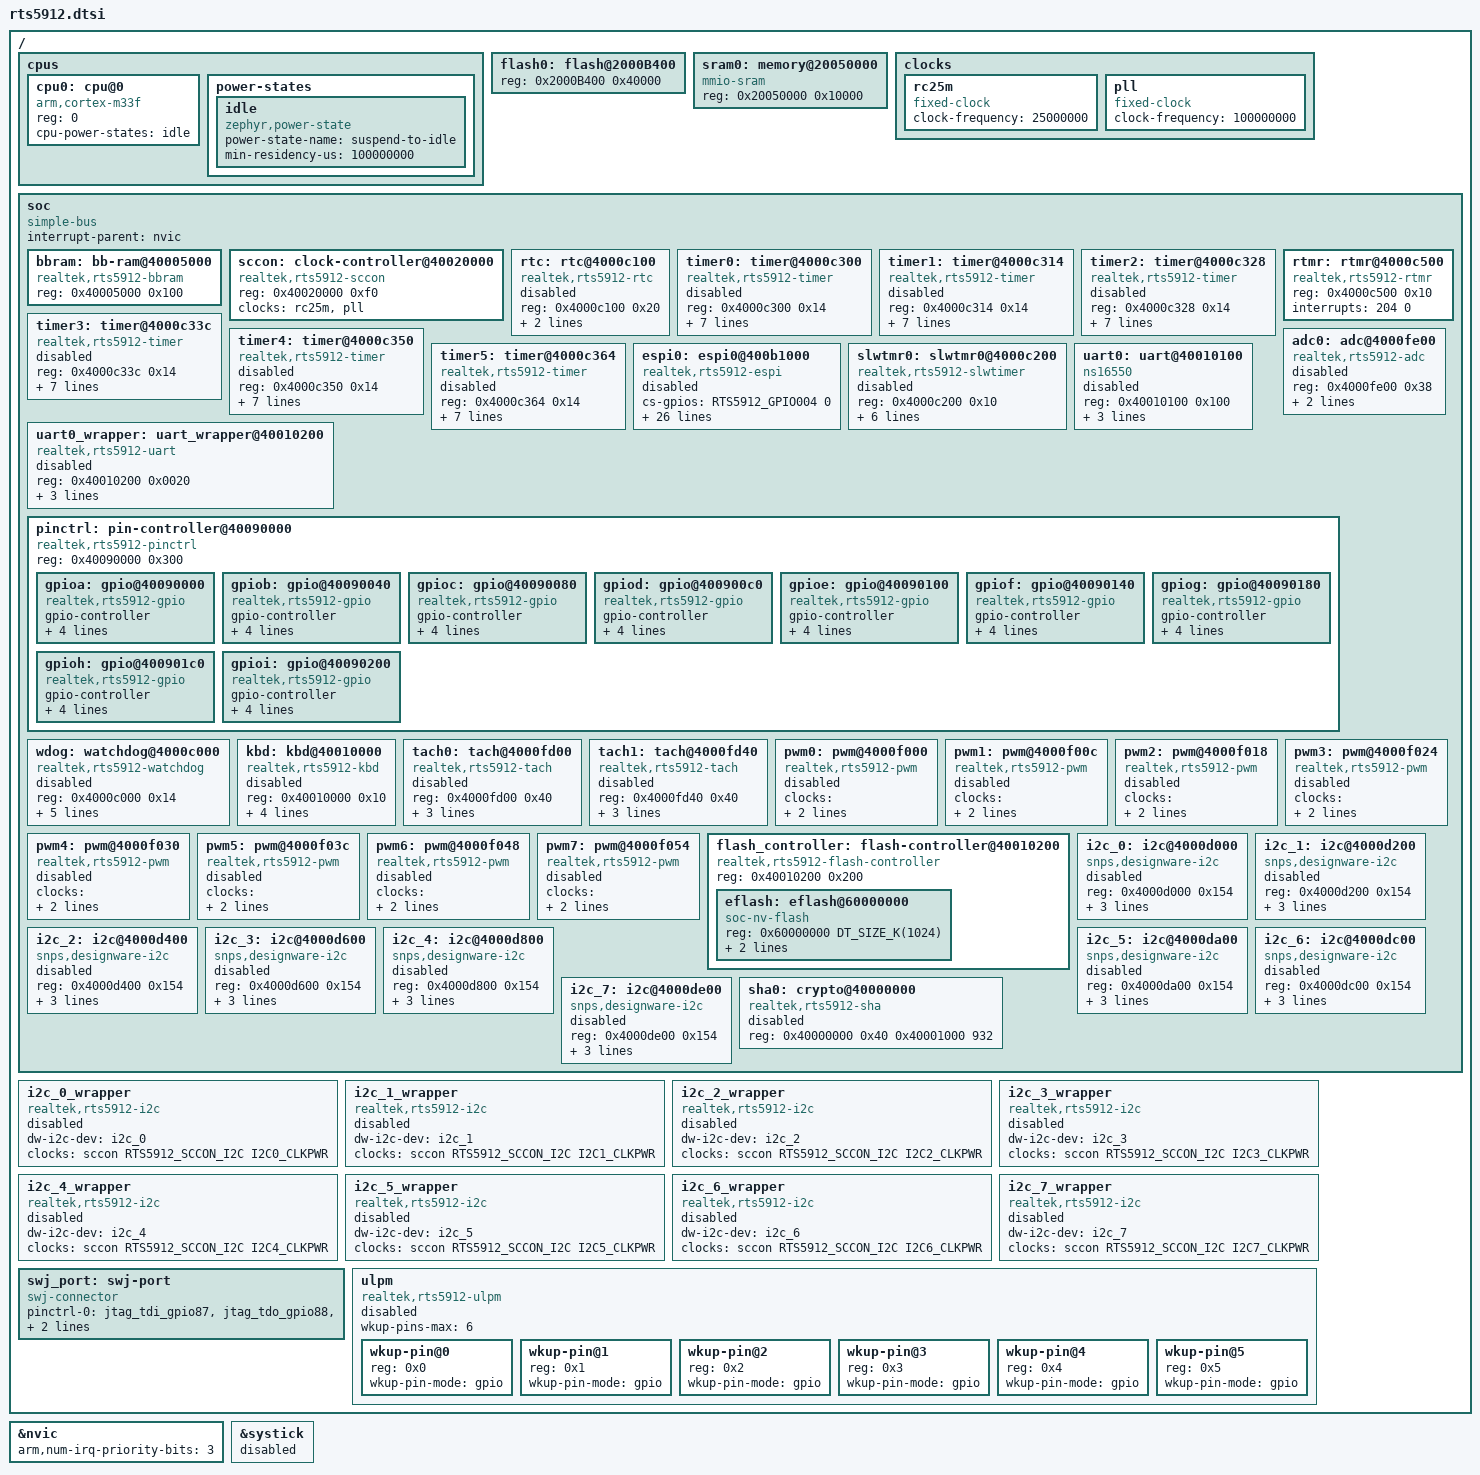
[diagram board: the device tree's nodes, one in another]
/*
 * SPDX-License-Identifier: Apache-2.0
 *
 * Copyright (c) 2024 Realtek Semiconductor Corporation, SIBG-SD7
 *
 */

#include <arm/armv8-m.dtsi>
#include <zephyr/dt-bindings/adc/adc.h>
#include <zephyr/dt-bindings/clock/rts5912_clock.h>
#include <zephyr/dt-bindings/gpio/realtek-gpio.h>
#include <zephyr/dt-bindings/pwm/pwm.h>
#include <mem.h>
#include <zephyr/dt-bindings/i2c/i2c.h>
#include <freq.h>
#include <zephyr/dt-bindings/gpio/realtek-gpio.h>

/ {
	cpus {
		#address-cells = <1>;
		#size-cells = <0>;

		cpu0: cpu@0 {
			compatible = "arm,cortex-m33f";
			reg = <0>;
			cpu-power-states = <&idle>;
		};

		power-states {
			idle: idle {
				compatible = "zephyr,power-state";
				power-state-name = "suspend-to-idle";
				min-residency-us = <100000000>;
			};
		};
	};

	flash0: flash@2000B400 {
		reg = <0x2000B400 0x40000>;
	};

	sram0: memory@20050000 {
		compatible = "mmio-sram";
		reg = <0x20050000 0x10000>;
	};

	clocks {
		rc25m: rc25m {
			compatible = "fixed-clock";
			clock-frequency = <25000000>;
			#clock-cells = <0>;
		};

		pll: pll {
			compatible = "fixed-clock";
			clock-frequency = <100000000>;
			#clock-cells = <0>;
		};
	};

	soc {
		#address-cells = <1>;
		#size-cells = <1>;
		compatible = "simple-bus";
		interrupt-parent = <&nvic>;
		ranges;

		bbram: bb-ram@40005000 {
			compatible = "realtek,rts5912-bbram";
			reg = <0x40005000 0x100>;
			status = "okay";
		};

		sccon: clock-controller@40020000 {
			compatible = "realtek,rts5912-sccon";
			reg = <0x40020000 0xf0>;
			#clock-cells = <2>;
			clocks = <&rc25m>, <&pll>;
			clock-names = "rc25m", "pll";
		};

		rtc: rtc@4000c100 {
			compatible = "realtek,rts5912-rtc";
			reg = <0x4000c100 0x20>;
			clocks = <&sccon RTS5912_SCCON_PERIPH_GRP2 PERIPH_GRP2_RTC_CLKPWR>;
			clock-names = "rtc";
			status = "disabled";
		};

		timer0: timer@4000c300 {
			compatible = "realtek,rts5912-timer";
			reg = <0x4000c300 0x14>;
			interrupt-parent = <&nvic>;
			interrupts = <196 1>;
			clocks = <&sccon RTS5912_SCCON_PERIPH_GRP1 PERIPH_GRP1_TMR0_CLKPWR>;
			clock-names = "tmr32";
			max-value = <0xFFFFFFFF>;
			clock-frequency = <25000000>;
			prescaler = <0>;
			status = "disabled";
		};

		timer1: timer@4000c314 {
			compatible = "realtek,rts5912-timer";
			reg = <0x4000c314 0x14>;
			interrupt-parent = <&nvic>;
			interrupts = <197 1>;
			clocks = <&sccon RTS5912_SCCON_PERIPH_GRP1 PERIPH_GRP1_TMR1_CLKPWR>;
			clock-names = "tmr32";
			max-value = <0xFFFFFFFF>;
			clock-frequency = <25000000>;
			prescaler = <0>;
			status = "disabled";
		};

		timer2: timer@4000c328 {
			compatible = "realtek,rts5912-timer";
			reg = <0x4000c328 0x14>;
			interrupt-parent = <&nvic>;
			interrupts = <198 1>;
			clocks = <&sccon RTS5912_SCCON_PERIPH_GRP1 PERIPH_GRP1_TMR2_CLKPWR>;
			clock-names = "tmr32";
			max-value = <0xFFFFFFFF>;
			clock-frequency = <25000000>;
			prescaler = <0>;
			status = "disabled";
		};

		timer3: timer@4000c33c {
			compatible = "realtek,rts5912-timer";
			reg = <0x4000c33c 0x14>;
			interrupt-parent = <&nvic>;
			interrupts = <199 1>;
			clocks = <&sccon RTS5912_SCCON_PERIPH_GRP1 PERIPH_GRP1_TMR3_CLKPWR>;
			clock-names = "tmr32";
			max-value = <0xFFFFFFFF>;
			clock-frequency = <25000000>;
			prescaler = <0>;
			status = "disabled";
		};

		timer4: timer@4000c350 {
			compatible = "realtek,rts5912-timer";
			reg = <0x4000c350 0x14>;
			interrupt-parent = <&nvic>;
			interrupts = <200 1>;
			clocks = <&sccon RTS5912_SCCON_PERIPH_GRP1 PERIPH_GRP1_TMR4_CLKPWR>;
			clock-names = "tmr32";
			max-value = <0xFFFFFFFF>;
			clock-frequency = <25000000>;
			prescaler = <0>;
			status = "disabled";
		};

		timer5: timer@4000c364 {
			compatible = "realtek,rts5912-timer";
			reg = <0x4000c364 0x14>;
			interrupt-parent = <&nvic>;
			interrupts = <201 1>;
			clocks = <&sccon RTS5912_SCCON_PERIPH_GRP1 PERIPH_GRP1_TMR5_CLKPWR>;
			clock-names = "tmr32";
			max-value = <0xFFFFFFFF>;
			clock-frequency = <25000000>;
			prescaler = <0>;
			status = "disabled";
		};

		espi0: espi0@400b1000 {
			compatible = "realtek,rts5912-espi";
			cs-gpios = <RTS5912_GPIO004 0>;
			status = "disabled";

			reg = <0x400b1000 0x200		/* espi target */
			       0x400a0400 0x01c		/* port80 */
			       0x400a0200 0x1c			/* ACPI */
			       0x400A021C 0x1C			/* PROMT0 */
			       0x400A0238 0x1C			/* PROMT1 */
			       0x400A0254 0x1C			/* PROMT2 */
			       0x400A0270 0x1C			/* PROMT3 */
			       0x40082000 0x14			/* EMI0 */
			       0x40082020 0x14			/* EMI1 */
			       0x40082040 0x14			/* EMI2 */
			       0x40082060 0x14			/* EMI3 */
			       0x40082080 0x14			/* EMI4 */
			       0x400820A0 0x14			/* EMI5 */
			       0x400820C0 0x14			/* EMI6 */
			       0x400820E0 0x14			/* EMI7 */
			       0x400a0100 0x1c			/* KBC */
			       0x400B1600 0xd0>;		/* MBX */

			reg-names = "espi_target", "port80", "acpi", "promt0", "promt1", "promt2",
				    "promt3", "emi0", "emi1", "emi2", "emi3", "emi4", "emi5",
				    "emi6", "emi7", "kbc", "mbx";

			clocks = <&sccon RTS5912_SCCON_PERIPH_GRP0 PERIPH_GRP0_ESPI_CLKPWR>,
				 <&sccon RTS5912_SCCON_PERIPH_GRP0 PERIPH_GRP0_P80_CLKPWR>,
				 <&sccon RTS5912_SCCON_PERIPH_GRP0 PERIPH_GRP0_ACPI_CLKPWR>,
				 <&sccon RTS5912_SCCON_PERIPH_GRP0 PERIPH_GRP0_PMPORT0_CLKPWR>,
				 <&sccon RTS5912_SCCON_PERIPH_GRP0 PERIPH_GRP0_PMPORT1_CLKPWR>,
				 <&sccon RTS5912_SCCON_PERIPH_GRP0 PERIPH_GRP0_PMPORT2_CLKPWR>,
				 <&sccon RTS5912_SCCON_PERIPH_GRP0 PERIPH_GRP0_PMPORT3_CLKPWR>,
				 <&sccon RTS5912_SCCON_PERIPH_GRP0 PERIPH_GRP0_EMI0_CLKPWR>,
				 <&sccon RTS5912_SCCON_PERIPH_GRP0 PERIPH_GRP0_EMI1_CLKPWR>,
				 <&sccon RTS5912_SCCON_PERIPH_GRP1 PERIPH_GRP1_EMI2_CLKPWR>,
				 <&sccon RTS5912_SCCON_PERIPH_GRP1 PERIPH_GRP1_EMI3_CLKPWR>,
				 <&sccon RTS5912_SCCON_PERIPH_GRP1 PERIPH_GRP1_EMI4_CLKPWR>,
				 <&sccon RTS5912_SCCON_PERIPH_GRP1 PERIPH_GRP1_EMI5_CLKPWR>,
				 <&sccon RTS5912_SCCON_PERIPH_GRP1 PERIPH_GRP1_EMI6_CLKPWR>,
				 <&sccon RTS5912_SCCON_PERIPH_GRP1 PERIPH_GRP1_EMI7_CLKPWR>,
				 <&sccon RTS5912_SCCON_PERIPH_GRP0 PERIPH_GRP0_KBC_CLKPWR>;

			clock-names = "espi-target", "port80", "acpi", "promt0", "promt1", "promt2",
				      "promt3", "emi0", "emi1", "emi2", "emi3", "emi4", "emi5",
				      "emi6", "emi7", "kbc";

			interrupts = <133 1>, <134 1>, <146 1>,
				     <145 1>, <144 1>, <143 1>,
				     <142 1>, <141 1>, <140 1>,
				     <139 1>, <138 1>, <137 1>,
				     <136 1>, <135 1>, <154 1>,
				     <155 1>, <156 1>, <157 1>,
				     <158 1>, <159 1>, <160 1>,
				     <161 1>, <162 1>, <163 1>,
				     <164 1>, <165 1>, <212 1>,
				     <213 1>, <214 1>, <215 1>,
				     <216 1>, <217 1>, <218 1>,
				     <219 1>, <147 1>, <148 1>,
				     <149 1>, <152 1>, <153 1>,
				     <166 1>, <220 1>;

			interrupt-names = "bus-rst", "periph-ch", "vw-ch",
					  "vw-idx2", "vw-idx3", "vw-idx7",
					  "vw-idx41", "vw-idx42", "vw-idx43",
					  "vw-idx44", "vw-idx47", "vw-idx4a",
					  "vw-idx51", "vw-idx61", "kbc_ibf",
					  "kbc_obe", "acpi_ibf", "acpi_obe",
					  "promt0_ibf", "promt0_obe", "promt1_ibf",
					  "promt1_obe", "promt2_ibf", "promt2_obe",
					  "promt3_ibf", "promt3_obe", "emi0",
					  "emi1", "emi2", "emi3",
					  "emi4", "emi5", "emi6",
					  "emi7", "oob_tx", "oob_rx",
					  "oob_chg", "maf_tr", "flash_chg",
					  "port80", "mbx";
		};

		slwtmr0: slwtmr0@4000c200 {
			compatible = "realtek,rts5912-slwtimer";
			reg = <0x4000c200 0x10>;
			interrupts = <202 1>;
			clocks = <&sccon RTS5912_SCCON_PERIPH_GRP1 PERIPH_GRP1_SLWTMR0_CLKPWR>;
			clock-names = "slwtmr";
			max-value = <0xFFFFFFFF>;
			clock-frequency = <1000000>;
			prescaler = <0>;
			status = "disabled";
		};

		rtmr: rtmr@4000c500 {
			compatible = "realtek,rts5912-rtmr";
			reg = <0x4000c500 0x10>;
			interrupts = <204 0>;
			status = "okay";
		};

		adc0: adc@4000fe00 {
			compatible = "realtek,rts5912-adc";
			reg = <0x4000fe00 0x38>;
			clocks = <&sccon RTS5912_SCCON_ADC ADC0_CLKPWR>;
			interrupts = <221 1>;
			#io-channel-cells = <1>;
			status = "disabled";
		};

		uart0: uart@40010100 {
			compatible = "ns16550";
			reg = <0x40010100 0x100>;
			reg-shift = <2>;
			clock-frequency = <DT_FREQ_M(100)>;
			interrupts = <191 1>;
			status = "disabled";
		};

		uart0_wrapper: uart_wrapper@40010200 {
			compatible = "realtek,rts5912-uart";
			reg = <0x40010200 0x0020>;
			port = <0>;
			clocks = <&sccon RTS5912_SCCON_UART UART0_CLKPWR>;
			clock-names = "uart0";
			status = "disabled";
			uart-dev = <&uart0>;
		};

		pinctrl: pin-controller@40090000 {
			compatible = "realtek,rts5912-pinctrl";
			#address-cells = <1>;
			#size-cells = <1>;
			reg = <0x40090000 0x300>;

			/* GPIO0-GPIO15 */
			gpioa: gpio@40090000 {
				compatible = "realtek,rts5912-gpio";
				gpio-controller;
				#gpio-cells = <2>;
				reg = <0x40090000 0x40>;
				ngpios = <16>;
				interrupts = <0 1 1 1 2 1 3 1
					      4 1 5 1 6 1 7 1
					      8 1 9 1 10 1 11 1
					      12 1 13 1 14 1 15 1>;
			};

			/* GPIO16-GPIO31 */
			gpiob: gpio@40090040 {
				compatible = "realtek,rts5912-gpio";
				gpio-controller;
				#gpio-cells = <2>;
				reg = <0x40090040 0x40>;
				ngpios = <16>;
				interrupts = <16 1 17 1 18 1 19 1
					      20 1 21 1 22 1 23 1
					      24 1 25 1 26 1 27 1
					      28 1 29 1 30 1 31 1>;
			};

			/* GPIO32-GPIO47 */
			gpioc: gpio@40090080 {
				compatible = "realtek,rts5912-gpio";
				gpio-controller;
				#gpio-cells = <2>;
				reg = <0x40090080 0x40>;
				ngpios = <16>;
				interrupts = <32 1 33 1 34 1 35 1
					      36 1 37 1 38 1 39 1
					      40 1 41 1 42 1 43 1
					      44 1 45 1 46 1 47 1>;
			};

			/* GPIO48-GPIO63 */
			gpiod: gpio@400900c0 {
				compatible = "realtek,rts5912-gpio";
				gpio-controller;
				#gpio-cells = <2>;
				reg = <0x400900c0 0x40>;
				ngpios = <16>;
				interrupts = <48 1 49 1 50 1 51 1
					      52 1 53 1 54 1 55 1
					      56 1 57 1 58 1 59 1
					      60 1 61 1 62 1 63 1>;
			};

			/* GPIO64-GPIO79 */
			gpioe: gpio@40090100 {
				compatible = "realtek,rts5912-gpio";
				gpio-controller;
				#gpio-cells = <2>;
				reg = <0x40090100 0x40>;
				ngpios = <16>;
				interrupts = <64 1 65 1 66 1 67 1
					      68 1 69 1 70 1 71 1
					      72 1 73 1 74 1 75 1
					      76 1 77 1 78 1 79 1>;
			};

			/* GPIO80-GPIO95 */
			gpiof: gpio@40090140 {
				compatible = "realtek,rts5912-gpio";
				gpio-controller;
				#gpio-cells = <2>;
				reg = <0x40090140 0x40>;
				ngpios = <16>;
				interrupts = <80 1 81 1 82 1 83 1
					      84 1 85 1 86 1 87 1
					      88 1 89 1 90 1 91 1
					      92 1 93 1 94 1 95 1>;
			};

			/* GPIO96-GPIO111 */
			gpiog: gpio@40090180 {
				compatible = "realtek,rts5912-gpio";
				gpio-controller;
				#gpio-cells = <2>;
				reg = <0x40090180 0x40>;
				ngpios = <16>;
				interrupts = <96 1 97 1 98 1 99 1
					      100 1 101 1 102 1 103 1
					      104 1 105 1 106 1 107 1
					      108 1 109 1 110 1 111 1>;
			};

			/* GPIO112-GPIO127 */
			gpioh: gpio@400901c0 {
				compatible = "realtek,rts5912-gpio";
				gpio-controller;
				#gpio-cells = <2>;
				reg = <0x400901c0 0x40>;
				ngpios = <16>;
				interrupts = <112 1 113 1 114 1 115 1
					      116 1 117 1 118 1 119 1
					      120 1 121 1 122 1 123 1
					      124 1 125 1 126 1 127 1>;
			};

			/* GPIO128-GPIO131 */
			gpioi: gpio@40090200 {
				compatible = "realtek,rts5912-gpio";
				gpio-controller;
				#gpio-cells = <2>;
				reg = <0x40090200 0x10>;
				ngpios = <4>;
				interrupts = <128 1 129 1 130 1 131 1
					      132 1 133 1 134 1 135 1
					      136 1 137 1 138 1 139 1
					      140 1 141 1 142 1 143 1>;
			};
		};

		wdog: watchdog@4000c000 {
			compatible = "realtek,rts5912-watchdog";
			reg = <0x4000c000 0x14>;
			interrupt-parent = <&nvic>;
			interrupts = <209 1>;
			clocks = <&sccon RTS5912_SCCON_PERIPH_GRP2 PERIPH_GRP2_WDT_CLKPWR>;
			clock-names = "watchdog";
			clk-divider = <33>;
			status = "disabled";
		};

		kbd: kbd@40010000 {
			compatible = "realtek,rts5912-kbd";
			reg = <0x40010000 0x10>;
			clocks = <&sccon RTS5912_SCCON_PERIPH_GRP0 PERIPH_GRP0_KBM_CLKPWR>;
			interrupts = <210 1>;
			interrupt-parent = <&nvic>;
			status = "disabled";
		};

		tach0: tach@4000fd00 {
			compatible = "realtek,rts5912-tach";
			reg = <0x4000fd00 0x40>;
			clocks = <&sccon RTS5912_SCCON_PERIPH_GRP0 PERIPH_GRP0_TACH0_CLKPWR>;
			clock-names = "tacho";
			interrupts = <192 1>;
			status = "disabled";
		};

		tach1: tach@4000fd40 {
			compatible = "realtek,rts5912-tach";
			reg = <0x4000fd40 0x40>;
			clocks = <&sccon RTS5912_SCCON_PERIPH_GRP0 PERIPH_GRP0_TACH1_CLKPWR>;
			clock-names = "tacho";
			interrupts = <193 1>;
			status = "disabled";
		};

		pwm0: pwm@4000f000 {
			compatible = "realtek,rts5912-pwm";
			clocks = <&sccon RTS5912_SCCON_PERIPH_GRP0 PERIPH_GRP0_PWM0_CLKPWR>;
			reg = <0x4000f000 0x0c>;
			status = "disabled";
			#pwm-cells = <3>;
		};

		pwm1: pwm@4000f00c {
			compatible = "realtek,rts5912-pwm";
			clocks = <&sccon RTS5912_SCCON_PERIPH_GRP0 PERIPH_GRP0_PWM1_CLKPWR>;
			reg = <0x4000f00c 0x0c>;
			status = "disabled";
			#pwm-cells = <3>;
		};

		pwm2: pwm@4000f018 {
			compatible = "realtek,rts5912-pwm";
			clocks = <&sccon RTS5912_SCCON_PERIPH_GRP0 PERIPH_GRP0_PWM2_CLKPWR>;
			reg = <0x4000f018 0x0c>;
			status = "disabled";
			#pwm-cells = <3>;
		};

		pwm3: pwm@4000f024 {
			compatible = "realtek,rts5912-pwm";
			clocks = <&sccon RTS5912_SCCON_PERIPH_GRP0 PERIPH_GRP0_PWM3_CLKPWR>;
			reg = <0x4000f024 0x0c>;
			status = "disabled";
			#pwm-cells = <3>;
		};

		pwm4: pwm@4000f030 {
			compatible = "realtek,rts5912-pwm";
			clocks = <&sccon RTS5912_SCCON_PERIPH_GRP0 PERIPH_GRP0_PWM4_CLKPWR>;
			reg = <0x4000f030 0x0c>;
			status = "disabled";
			#pwm-cells = <3>;
		};

		pwm5: pwm@4000f03c {
			compatible = "realtek,rts5912-pwm";
			clocks = <&sccon RTS5912_SCCON_PERIPH_GRP0 PERIPH_GRP0_PWM5_CLKPWR>;
			reg = <0x4000f03c 0x0c>;
			status = "disabled";
			#pwm-cells = <3>;
		};

		pwm6: pwm@4000f048 {
			compatible = "realtek,rts5912-pwm";
			clocks = <&sccon RTS5912_SCCON_PERIPH_GRP0 PERIPH_GRP0_PWM6_CLKPWR>;
			reg = <0x4000f048 0x0c>;
			status = "disabled";
			#pwm-cells = <3>;
		};

		pwm7: pwm@4000f054 {
			compatible = "realtek,rts5912-pwm";
			clocks = <&sccon RTS5912_SCCON_PERIPH_GRP0 PERIPH_GRP0_PWM7_CLKPWR>;
			reg = <0x4000f054 0x0c>;
			status = "disabled";
			#pwm-cells = <3>;
		};

		flash_controller: flash-controller@40010200 {
			compatible = "realtek,rts5912-flash-controller";
			reg = <0x40010200 0x200>;
			#address-cells = <1>;
			#size-cells = <1>;

			eflash: eflash@60000000 {
				compatible = "soc-nv-flash";
				reg = <0x60000000 DT_SIZE_K(1024)>;
				erase-block-size = <DT_SIZE_K(4)>;
				write-block-size = <4>;
			};
		};

		i2c_0: i2c@4000d000 {
			compatible = "snps,designware-i2c";
			reg = <0x4000d000 0x154>;
			clock-frequency = <I2C_BITRATE_STANDARD>;
			interrupt-parent = <&nvic>;
			interrupts = <182 2>;
			status = "disabled";
			#address-cells = <1>;
			#size-cells = <0>;
		};

		i2c_1: i2c@4000d200 {
			compatible = "snps,designware-i2c";
			reg = <0x4000d200 0x154>;
			clock-frequency = <I2C_BITRATE_STANDARD>;
			interrupt-parent = <&nvic>;
			interrupts = <183 2>;
			status = "disabled";
			#address-cells = <1>;
			#size-cells = <0>;
		};

		i2c_2: i2c@4000d400 {
			compatible = "snps,designware-i2c";
			reg = <0x4000d400 0x154>;
			clock-frequency = <I2C_BITRATE_STANDARD>;
			interrupt-parent = <&nvic>;
			interrupts = <184 2>;
			status = "disabled";
			#address-cells = <1>;
			#size-cells = <0>;
		};

		i2c_3: i2c@4000d600 {
			compatible = "snps,designware-i2c";
			reg = <0x4000d600 0x154>;
			clock-frequency = <I2C_BITRATE_STANDARD>;
			interrupt-parent = <&nvic>;
			interrupts = <185 2>;
			status = "disabled";
			#address-cells = <1>;
			#size-cells = <0>;
		};

		i2c_4: i2c@4000d800 {
			compatible = "snps,designware-i2c";
			reg = <0x4000d800 0x154>;
			clock-frequency = <I2C_BITRATE_STANDARD>;
			interrupt-parent = <&nvic>;
			interrupts = <186 2>;
			status = "disabled";
			#address-cells = <1>;
			#size-cells = <0>;
		};

		i2c_5: i2c@4000da00 {
			compatible = "snps,designware-i2c";
			reg = <0x4000da00 0x154>;
			clock-frequency = <I2C_BITRATE_STANDARD>;
			interrupt-parent = <&nvic>;
			interrupts = <187 2>;
			status = "disabled";
			#address-cells = <1>;
			#size-cells = <0>;
		};

		i2c_6: i2c@4000dc00 {
			compatible = "snps,designware-i2c";
			reg = <0x4000dc00 0x154>;
			clock-frequency = <I2C_BITRATE_STANDARD>;
			interrupt-parent = <&nvic>;
			interrupts = <188 2>;
			status = "disabled";
			#address-cells = <1>;
			#size-cells = <0>;
		};

		i2c_7: i2c@4000de00 {
			compatible = "snps,designware-i2c";
			reg = <0x4000de00 0x154>;
			clock-frequency = <I2C_BITRATE_STANDARD>;
			interrupt-parent = <&nvic>;
			interrupts = <189 2>;
			status = "disabled";
			#address-cells = <1>;
			#size-cells = <0>;
		};

		sha0: crypto@40000000 {
			compatible = "realtek,rts5912-sha";
			reg = <0x40000000 0x40 0x40001000 932>;
			reg-names = "sha2", "sha2dma";
			status = "disabled";
		};
	};

	i2c_0_wrapper: i2c_0_wrapper {
		compatible = "realtek,rts5912-i2c";
		dw-i2c-dev = <&i2c_0>;
		clocks = <&sccon RTS5912_SCCON_I2C I2C0_CLKPWR>;
		clock-names = "i2c";
		status = "disabled";
	};

	i2c_1_wrapper: i2c_1_wrapper {
		compatible = "realtek,rts5912-i2c";
		dw-i2c-dev = <&i2c_1>;
		clocks = <&sccon RTS5912_SCCON_I2C I2C1_CLKPWR>;
		clock-names = "i2c";
		status = "disabled";
	};

	i2c_2_wrapper: i2c_2_wrapper {
		compatible = "realtek,rts5912-i2c";
		dw-i2c-dev = <&i2c_2>;
		clocks = <&sccon RTS5912_SCCON_I2C I2C2_CLKPWR>;
		clock-names = "i2c";
		status = "disabled";
	};

	i2c_3_wrapper: i2c_3_wrapper {
		compatible = "realtek,rts5912-i2c";
		dw-i2c-dev = <&i2c_3>;
		clocks = <&sccon RTS5912_SCCON_I2C I2C3_CLKPWR>;
		clock-names = "i2c";
		status = "disabled";
	};

	i2c_4_wrapper: i2c_4_wrapper {
		compatible = "realtek,rts5912-i2c";
		dw-i2c-dev = <&i2c_4>;
		clocks = <&sccon RTS5912_SCCON_I2C I2C4_CLKPWR>;
		clock-names = "i2c";
		status = "disabled";
	};

	i2c_5_wrapper: i2c_5_wrapper {
		compatible = "realtek,rts5912-i2c";
		dw-i2c-dev = <&i2c_5>;
		clocks = <&sccon RTS5912_SCCON_I2C I2C5_CLKPWR>;
		clock-names = "i2c";
		status = "disabled";
	};

	i2c_6_wrapper: i2c_6_wrapper {
		compatible = "realtek,rts5912-i2c";
		dw-i2c-dev = <&i2c_6>;
		clocks = <&sccon RTS5912_SCCON_I2C I2C6_CLKPWR>;
		clock-names = "i2c";
		status = "disabled";
	};

	i2c_7_wrapper: i2c_7_wrapper {
		compatible = "realtek,rts5912-i2c";
		dw-i2c-dev = <&i2c_7>;
		clocks = <&sccon RTS5912_SCCON_I2C I2C7_CLKPWR>;
		clock-names = "i2c";
		status = "disabled";
	};

	swj_port: swj-port {
		compatible = "swj-connector";
		pinctrl-0 = <&jtag_tdi_gpio87 &jtag_tdo_gpio88 &jtag_rst_gpio89
			     &jtag_clk_gpio90 &jtag_tms_gpio91>;
		pinctrl-names = "default";
	};

	ulpm: ulpm {
		compatible = "realtek,rts5912-ulpm";
		wkup-pins-max = <6>; /* 6 system wake-up pins */
		status = "disabled";

		#address-cells = <1>;
		#size-cells = <0>;

		wkup-pin@0 {
			reg = <0x0>;
			wkup-pin-mode = "gpio";
		};

		wkup-pin@1 {
			reg = <0x1>;
			wkup-pin-mode = "gpio";
		};

		wkup-pin@2 {
			reg = <0x2>;
			wkup-pin-mode = "gpio";
		};

		wkup-pin@3 {
			reg = <0x3>;
			wkup-pin-mode = "gpio";
		};

		wkup-pin@4 {
			reg = <0x4>;
			wkup-pin-mode = "gpio";
		};

		wkup-pin@5 {
			reg = <0x5>;
			wkup-pin-mode = "gpio";
		};
	};
};

&nvic {
	arm,num-irq-priority-bits = <3>;
};

&systick {
	status = "disabled";
};
